# earlgrey register map
File version: 0.1
Address unit: 32 bits
Registers are 32-bit, read-write, no defined reset value unless marked. A register's access mark holds for its fields unless they carry their own. Offsets are from the block's base; [hi:lo] are bit positions.

## entropy_src — Filters and checks raw entropy bits from a random noise source and forwards them to CSRNG
Base 0x41160000
0x00 ME_REGWEN rw0c — Register write enable for module enable register
  [?] ? — When true, the !!MODULE_ENABLE register can be modified.When false, it becomes read-only.
0x20 SW_REGUPD rw0c — Register write enable for control and threshold registers
  [?] ? — When this bit true and the MODULE_ENABLE field is false,the REGWEN write enable bit read as true, and is distributed toall associated control and threshold registers.When false, these registers become read-only.
0x40 REGWEN ro — Register write enable for all control registers
  [?] ? — This read-only write enable bit will allow write accessto control and theshold registers that are associated with this bit,but only when the MODULE_ENABLE field is set to kMultiBitBool4False and theSW_REGUPD write enable bit is set to true.When read as false, these registers become read-only.
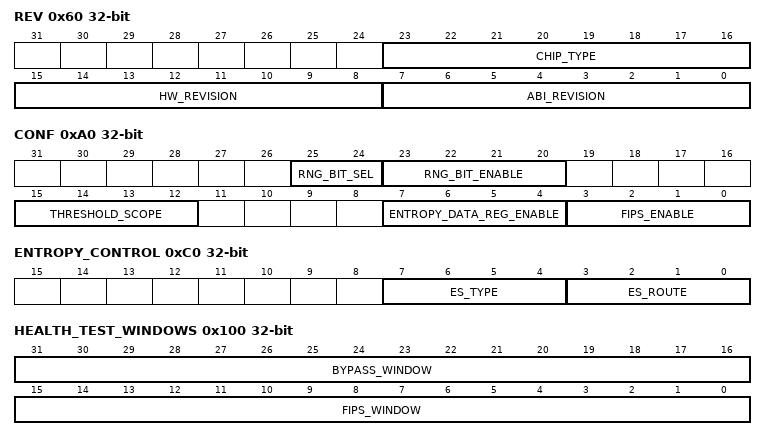
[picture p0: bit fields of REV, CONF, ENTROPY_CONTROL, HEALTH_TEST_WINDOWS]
0x60 REV ro — Revision register
  [23:16] CHIP_TYPE — Read of this register shows the type of chip using this block.
  [15:8] HW_REVISION — Read of this register shows the revision of this block.
  [7:0] ABI_REVISION — Read of this register shows the ABI of this block.
0x80 MODULE_ENABLE
  [3:0] MODULE_ENABLE — Setting this field to kMultiBitBool4True will enable the ENTROPY_SRC module. Settingthis field to kMultiBitBool4False will effectively reset the module. The modules ofthe entropy complex may only be enabled and disabled in a specific order, seeProgrammers Guide for details.
0xA0 CONF — Configuration register
  [25:24] RNG_BIT_SEL — When the above bit iset, this field selects which bit from the RNG bus willbe processed when in single RNG bit mode.This two bit field selects the RNG bit stream:0b00: RNG bit 00b01: RNG bit 10b10: RNG bit 20b11: RNG bit 3
  [23:20] RNG_BIT_ENABLE — Setting this field to kMultiBitBool4True enables the single RNG bit mode, where onlyone bit is sampled.
  [15:12] THRESHOLD_SCOPE — This field controls the scope (either by-line or by-sum) of the health checks.If set to kMultiBitBool4True, the Adaptive Proportion and Markov Tests will accumulate allRNG input lines into a single score, and thresholds will be applied to the sum allthe entropy input lines. If set to kMultiBitBool4False, the RNG input lines are all scoredindividually. A statistical deviation in any one input line, be it due tocoincidence or failure, will force rejection of the sample, and count toward thetotal alert count.
  [7:4] ENTROPY_DATA_REG_ENABLE — Setting this field to kMultiBitBool4True will enable reading entropy values from theENTROPY_DATA register. This function also requires that the otp_en_entropy_src_fw_readinput vector is set to the enable encoding.
  [3:0] FIPS_ENABLE — Setting this field to kMultiBitBool4True will enable FIPS qualified entropy to begenerated.
0xC0 ENTROPY_CONTROL
  [7:4] ES_TYPE — Setting this field to kMultiBitBool4True will bypass the conditioning logic and bring raw entropydata to the ENTROPY_DATA register. When kMultiBitBool4False, FIPS compliant entropywill be brought the ENTROPY_DATA register, after being conditioned.
  [3:0] ES_ROUTE — Setting this field to kMultiBitBool4True routes the generated entropy value to the ENTROPY_DATAregister to be read by firmware. When this field is kMultiBitBool4False, the generatedentropy will be forwarded out of this module to the hardware interface.
0xE0 ENTROPY_DATA ro — Entropy data bits
  [31:0] ? — A read of this register provides generated entropy bits to firmware.
0x100 HEALTH_TEST_WINDOWS
  [31:16] BYPASS_WINDOW — This is the window size for all health tests when running in bypass mode. This mode is active after reset for the first and only test run, or when this mode is programmed by firmware. The default value is (384 bits * 1 clock/4 bits); Note that currently only a window size of 384 is supported and tested (this corresponds to the register default value 0x60). Do not use any other values, unless you know what you are doing.
  [15:0] FIPS_WINDOW — This is the window size for all health tests. This value is used in normal mode when entropy is being tested in FIPS/CC compliance mode. The default value is (2048 bits * 1 clock/4 bits);
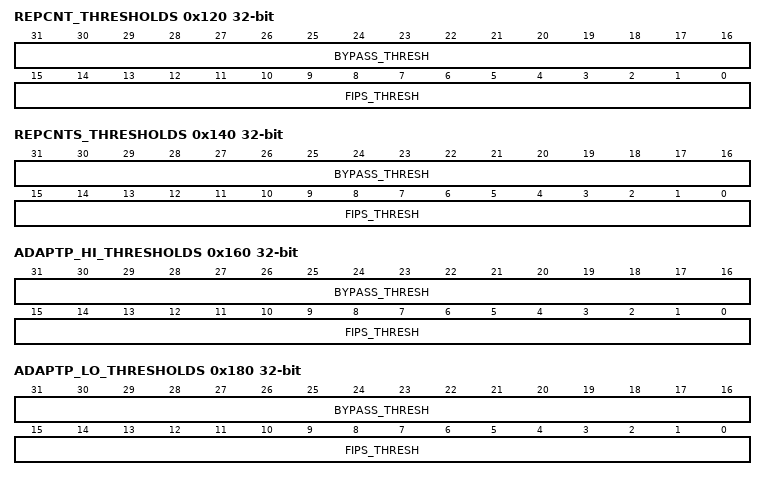
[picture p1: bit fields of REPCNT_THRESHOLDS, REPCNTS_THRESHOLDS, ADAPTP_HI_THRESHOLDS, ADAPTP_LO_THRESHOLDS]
0x120 REPCNT_THRESHOLDS — Repetition count test thresholds register
  [31:16] BYPASS_THRESH — This is the threshold size for the repetition count health test running in bypass mode. This mode is active after reset for the first and only test run, or when this mode is programmed by firmware. This register must be written before the module is enabled. Writing to this register will only update the register if the written value is less than the current value of this register. A read from this register always reflects the current value.
  [15:0] FIPS_THRESH — This is the threshold size for the repetition count health test. This value is used in normal mode when entropy is being tested in FIPS/CC compliance mode. This register must be written before the module is enabled. Writing to this register will only update the register if the written value is less than the current value of this register. A read from this register always reflects the current value.
0x140 REPCNTS_THRESHOLDS — Repetition count symbol test thresholds register
  [31:16] BYPASS_THRESH — This is the threshold size for the repetition count symbol health test running in bypass mode. This mode is active after reset for the first and only test run, or when this mode is programmed by firmware. This register must be written before the module is enabled. Writing to this register will only update the register if the written value is less than the current value of this register. A read from this register always reflects the current value.
  [15:0] FIPS_THRESH — This is the threshold size for the repetition count symbol health test. This value is used in normal mode when entropy is being tested in FIPS/CC compliance mode. This register must be written before the module is enabled. Writing to this register will only update the register if the written value is less than the current value of this register. A read from this register always reflects the current value.
0x160 ADAPTP_HI_THRESHOLDS — Adaptive proportion test high thresholds register
  [31:16] BYPASS_THRESH — This is the threshold size for the adaptive proportion health test running in bypass mode. This mode is active after reset for the first and only test run, or when this mode is programmed by firmware. This register must be written before the module is enabled. Writing to this register will only update the register if the written value is less than the current value of this register. A read from this register always reflects the current value.
  [15:0] FIPS_THRESH — This is the threshold size for the adaptive proportion health test. This value is used in normal mode when entropy is being tested in FIPS/CC compliance mode. This register must be written before the module is enabled. Writing to this register will only update the register if the written value is less than the current value of this register. A read from this register always reflects the current value.
0x180 ADAPTP_LO_THRESHOLDS — Adaptive proportion test low thresholds register
  [31:16] BYPASS_THRESH — This is the threshold size for the adaptive proportion health test running in bypass mode. This mode is active after reset for the first and only test run, or when this mode is programmed by firmware. This register must be written before the module is enabled. Writing to this register will only update the register if the written value is greater than the current value of this register. A read from this register always reflects the current value.
  [15:0] FIPS_THRESH — This is the threshold size for the adaptive proportion health test. This value is used in normal mode when entropy is being tested in FIPS/CC compliance mode. This register must be written before the module is enabled. Writing to this register will only update the register if the written value is greater than the current value of this register. A read from this register always reflects the current value.
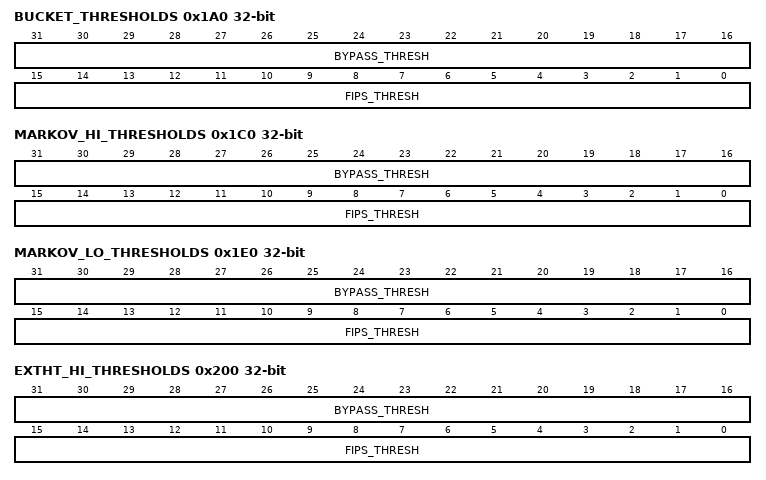
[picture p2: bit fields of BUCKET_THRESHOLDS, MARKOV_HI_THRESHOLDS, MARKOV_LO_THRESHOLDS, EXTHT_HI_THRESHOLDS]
0x1A0 BUCKET_THRESHOLDS — Bucket test thresholds register
  [31:16] BYPASS_THRESH — This is the threshold size for the bucket health test running in bypass mode. This mode is active after reset for the first and only test run, or when this mode is programmed by firmware. This register must be written before the module is enabled. Writing to this register will only update the register if the written value is less than the current value of this register. A read from this register always reflects the current value.
  [15:0] FIPS_THRESH — This is the threshold size for the bucket health test. This value is used in normal mode when entropy is being tested in FIPS/CC compliance mode. This register must be written before the module is enabled. Writing to this register will only update the register if the written value is less than the current value of this register. A read from this register always reflects the current value.
0x1C0 MARKOV_HI_THRESHOLDS — Markov test high thresholds register
  [31:16] BYPASS_THRESH — This is the threshold size for the Markov health test running in bypass mode. This mode is active after reset for the first and only test run, or when this mode is programmed by firmware. This register must be written before the module is enabled. Writing to this register will only update the register if the written value is less than the current value of this register. A read from this register always reflects the current value.
  [15:0] FIPS_THRESH — This is the threshold size for the Markov health test. This value is used in normal mode when entropy is being tested in FIPS/CC compliance mode. This register must be written before the module is enabled. Writing to this register will only update the register if the written value is less than the current value of this register. A read from this register always reflects the current value.
0x1E0 MARKOV_LO_THRESHOLDS — Markov test low thresholds register
  [31:16] BYPASS_THRESH — This is the threshold size for the Markov health test running in bypass mode. This mode is active after reset for the first and only test run, or when this mode is programmed by firmware. This register must be written before the module is enabled. Writing to this register will only update the register if the written value is greater than the current value of this register. A read from this register always reflects the current value.
  [15:0] FIPS_THRESH — This is the threshold size for the Markov health test. This value is used in normal mode when entropy is being tested in FIPS/CC compliance mode. This register must be written before the module is enabled. Writing to this register will only update the register if the written value is greater than the current value of this register. A read from this register always reflects the current value.
0x200 EXTHT_HI_THRESHOLDS — External health test high thresholds register
  [31:16] BYPASS_THRESH — This is the threshold size for the external health test running in bypass mode. This mode is active after reset for the first and only test run, or when this mode is programmed by firmware. This register must be written before the module is enabled. Writing to this register will only update the register if the written value is less than the current value of this register. A read from this register always reflects the current value.
  [15:0] FIPS_THRESH — This is the threshold size for the external health test. This value is used in normal mode when entropy is being tested in FIPS/CC compliance mode. This register must be written before the module is enabled. Writing to this register will only update the register if the written value is less than the current value of this register. A read from this register always reflects the current value.
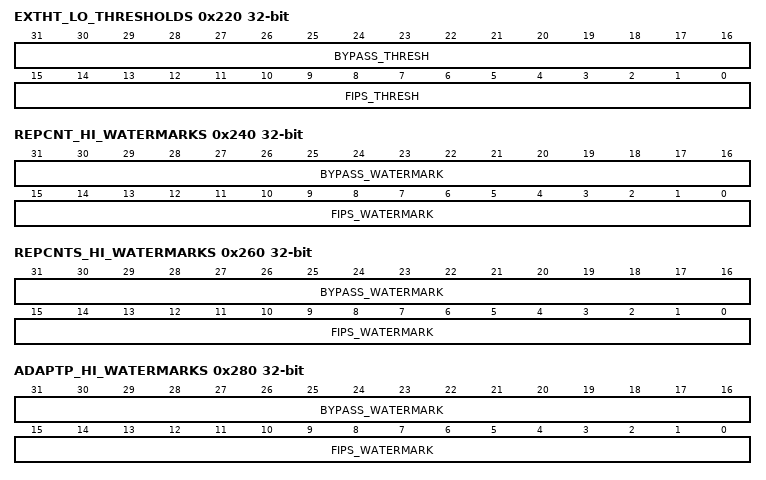
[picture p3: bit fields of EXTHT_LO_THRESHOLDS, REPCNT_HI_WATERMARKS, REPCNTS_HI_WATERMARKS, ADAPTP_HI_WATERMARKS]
0x220 EXTHT_LO_THRESHOLDS — External health test low thresholds register
  [31:16] BYPASS_THRESH — This is the threshold size for the external health test running in bypass mode. This mode is active after reset for the first and only test run, or when this mode is programmed by firmware. This register must be written before the module is enabled. Writing to this register will only update the register if the written value is greater than the current value of this register. A read from this register always reflects the current value.
  [15:0] FIPS_THRESH — This is the threshold size for the external health test. This value is used in normal mode when entropy is being tested in FIPS/CC compliance mode. This register must be written before the module is enabled. Writing to this register will only update the register if the written value is greater than the current value of this register. A read from this register always reflects the current value.
0x240 REPCNT_HI_WATERMARKS ro — Repetition count test high watermarks register
  [31:16] BYPASS_WATERMARK — High watermark value of the REPCNT test in bypass mode.
  [15:0] FIPS_WATERMARK — High watermark value of the REPCNT test in FIPS mode.
0x260 REPCNTS_HI_WATERMARKS ro — Repetition count symbol test high watermarks register
  [31:16] BYPASS_WATERMARK — High watermark value of the REPCNTS test in bypass mode.
  [15:0] FIPS_WATERMARK — High watermark value of the REPCNTS test in FIPS mode.
0x280 ADAPTP_HI_WATERMARKS ro — Adaptive proportion test high watermarks register
  [31:16] BYPASS_WATERMARK — High watermark value of the adaptive proportion test in bypass mode.
  [15:0] FIPS_WATERMARK — High watermark value of the adaptive proportion test in FIPS mode.
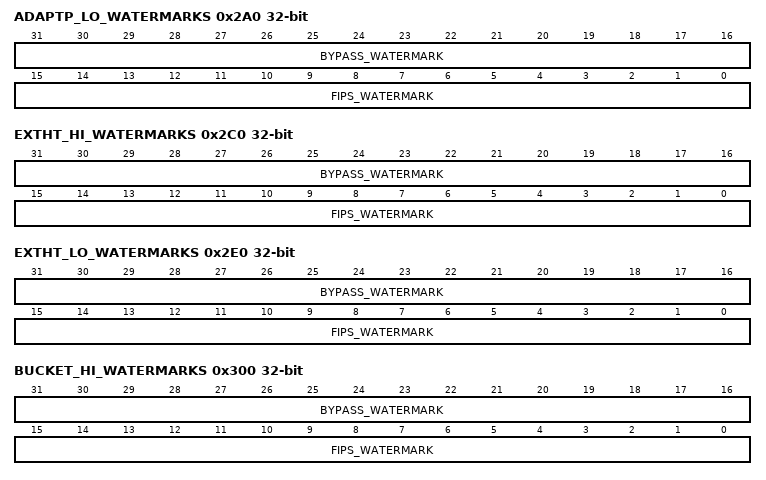
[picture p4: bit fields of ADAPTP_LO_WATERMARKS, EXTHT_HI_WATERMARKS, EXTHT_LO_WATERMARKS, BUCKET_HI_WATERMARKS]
0x2A0 ADAPTP_LO_WATERMARKS ro — Adaptive proportion test low watermarks register
  [31:16] BYPASS_WATERMARK — Low watermark value of the adaptive proportion test in bypass mode.
  [15:0] FIPS_WATERMARK — Low watermark value of the adaptive proportion test in FIPS mode.
0x2C0 EXTHT_HI_WATERMARKS ro — External health test high watermarks register
  [31:16] BYPASS_WATERMARK — High watermark value of the external health test in bypass mode.
  [15:0] FIPS_WATERMARK — High watermark value of the external health test in FIPS mode.
0x2E0 EXTHT_LO_WATERMARKS ro — External health test low watermarks register
  [31:16] BYPASS_WATERMARK — Low watermark value of the external health test in bypass mode.
  [15:0] FIPS_WATERMARK — Low watermark value of the external health test in FIPS mode.
0x300 BUCKET_HI_WATERMARKS ro — Bucket test high watermarks register
  [31:16] BYPASS_WATERMARK — High watermark value of the bucket test in bypass mode.
  [15:0] FIPS_WATERMARK — High watermark value of the bucket test in FIPS mode.
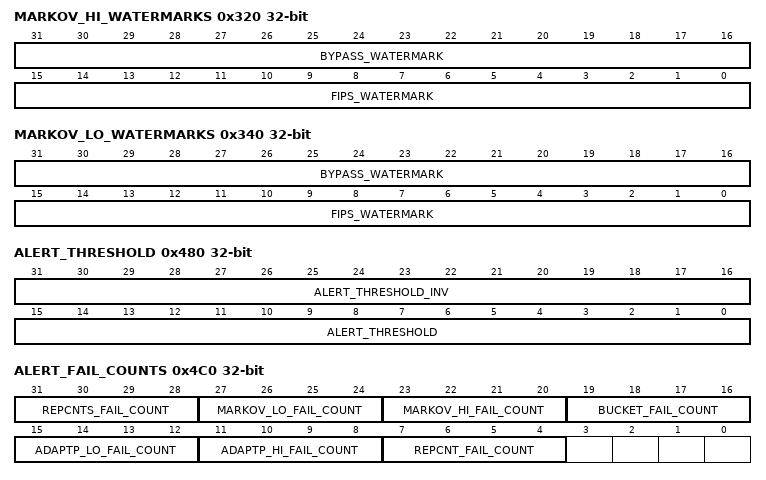
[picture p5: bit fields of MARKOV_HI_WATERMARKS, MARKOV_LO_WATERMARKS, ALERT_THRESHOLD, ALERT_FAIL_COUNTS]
0x320 MARKOV_HI_WATERMARKS ro — Markov test high watermarks register
  [31:16] BYPASS_WATERMARK — High watermark value of the Markov test in bypass mode.
  [15:0] FIPS_WATERMARK — High watermark value of the Markov test in FIPS mode.
0x340 MARKOV_LO_WATERMARKS ro — Markov test low watermarks register
  [31:16] BYPASS_WATERMARK — Low watermark value of the Markov test in bypass mode.
  [15:0] FIPS_WATERMARK — Low watermark value of the Markov test in FIPS mode.
0x360 REPCNT_TOTAL_FAILS ro — Repetition count test failure counter register
  [31:0] REPCNT_TOTAL_FAILS — This register will hold a running count of test failures observed during normal operation. It will persist until cleared.
0x380 REPCNTS_TOTAL_FAILS ro — Repetition count symbol test failure counter register
  [31:0] REPCNTS_TOTAL_FAILS — This register will hold a running count of test failures observed during normal operation. It will persist until cleared.
0x3A0 ADAPTP_HI_TOTAL_FAILS ro — Adaptive proportion high test failure counter register
  [31:0] ADAPTP_HI_TOTAL_FAILS — This register will hold a running count of test failures observed during normal operation. It will persist until cleared.
0x3C0 ADAPTP_LO_TOTAL_FAILS ro — Adaptive proportion low test failure counter register
  [31:0] ADAPTP_LO_TOTAL_FAILS — This register will hold a running count of test failures observed during normal operation. It will persist until cleared.
0x3E0 BUCKET_TOTAL_FAILS ro — Bucket test failure counter register
  [31:0] BUCKET_TOTAL_FAILS — This register will hold a running count of test failures observed during normal operation. It will persist until cleared.
0x400 MARKOV_HI_TOTAL_FAILS ro — Markov high test failure counter register
  [31:0] MARKOV_HI_TOTAL_FAILS — This register will hold a running count of test failures observed during normal operation. It will persist until cleared.
0x420 MARKOV_LO_TOTAL_FAILS ro — Markov low test failure counter register
  [31:0] MARKOV_LO_TOTAL_FAILS — This register will hold a running count of test failures observed during normal operation. It will persist until cleared.
0x440 EXTHT_HI_TOTAL_FAILS ro — External health test high threshold failure counter register
  [31:0] EXTHT_HI_TOTAL_FAILS — This register will hold a running count of test failures observed during normal operation. It will persist until cleared.
0x460 EXTHT_LO_TOTAL_FAILS ro — External health test low threshold failure counter register
  [31:0] EXTHT_LO_TOTAL_FAILS — This register will hold a running count of test failures observed during normal operation. It will persist until cleared.
0x480 ALERT_THRESHOLD
  [31:16] ALERT_THRESHOLD_INV — This should be set to the value above, but inverted.
  [15:0] ALERT_THRESHOLD — This is the threshold size that will signal an alert when value is reached. A value of zero will disable alerts. The default value is 2.
0x4A0 ALERT_SUMMARY_FAIL_COUNTS ro — Alert summary failure counts register
  [15:0] ANY_FAIL_COUNT — This field will hold a running count of the total alert count, which is a sum of all of the other counters in the !!ALERT_FAIL_COUNTS register. It will be reset after every passing test sequence. If an alert is signaled, this value will persist until it is cleared.
0x4C0 ALERT_FAIL_COUNTS ro — Alert failure counts register
  [31:28] REPCNTS_FAIL_COUNT — This field will hold a running count of test failures that contribute to the total alert count. It will be reset after every passing test sequence. If an alert is signaled, this value will persist until it is cleared.
  [27:24] MARKOV_LO_FAIL_COUNT — This field will hold a running count of test failures that contribute to the total alert count. It will be reset after every passing test sequence. If an alert is signaled, this value will persist until it is cleared.
  [23:20] MARKOV_HI_FAIL_COUNT — This field will hold a running count of test failures that contribute to the total alert count. It will be reset after every passing test sequence. If an alert is signaled, this value will persist until it is cleared.
  [19:16] BUCKET_FAIL_COUNT — This field will hold a running count of test failures that contribute to the total alert count. It will be reset after every passing test sequence. If an alert is signaled, this value will persist until it is cleared.
  [15:12] ADAPTP_LO_FAIL_COUNT — This field will hold a running count of test failures that contribute to the total alert count. It will be reset after every passing test sequence. If an alert is signaled, this value will persist until it is cleared.
  [11:8] ADAPTP_HI_FAIL_COUNT — This field will hold a running count of test failures that contribute to the total alert count. It will be reset after every passing test sequence. If an alert is signaled, this value will persist until it is cleared.
  [7:4] REPCNT_FAIL_COUNT — This field will hold a running count of test failures that contribute to the total alert count. It will be reset after every passing test sequence. If an alert is signaled, this value will persist until it is cleared.
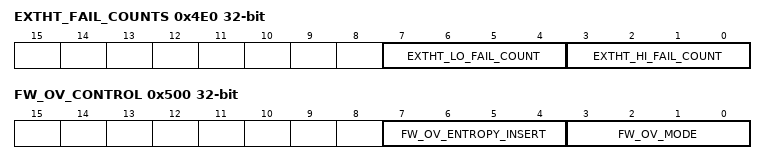
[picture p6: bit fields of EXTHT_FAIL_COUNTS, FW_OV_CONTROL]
0x4E0 EXTHT_FAIL_COUNTS ro — External health test alert failure counts register
  [7:4] EXTHT_LO_FAIL_COUNT — This field will hold a running count of test failures that contribute to the total alert count. It will be reset after every passing test sequence. If an alert is signaled, this value will persist until it is cleared.
  [3:0] EXTHT_HI_FAIL_COUNT — This field will hold a running count of test failures that contribute to the total alert count. It will be reset after every passing test sequence. If an alert is signaled, this value will persist until it is cleared.
0x500 FW_OV_CONTROL — Firmware override control register
  [7:4] FW_OV_ENTROPY_INSERT — Setting this field to kMultiBitBool4True will switch the input into the pre-conditionerpacker FIFO. Firmware can directly write into the packer FIFO, enablingthe ability to insert entropy bits back into the hardware flow. Firmwarecan read data from the health check packer FIFO, then do optional healthchecks or optional conditioning, then insert the results back into the flow.Also, the !!FW_OV_CONTROL.FW_OV_MODE bit must be set.
  [3:0] FW_OV_MODE — Setting this field to kMultiBitBool4True will put the entropy flow in firmware override mode.In this mode, firmware can monitor the post-health test entropy by readingthe observe FIFO. This function also requires that the otp_en_entropy_src_fw_overinput vector is set to the enable encoding.
0x520 FW_OV_SHA3_START — Firmware override sha3 block start control register
  [3:0] FW_OV_INSERT_START — Setting this field to kMultiBitBool4True will instruct the ENTROPY_SRC main state machineto start the SHA3 process and be ready to accept entropy data. This field shouldbe set prior to writting the FW_OV_WR_DATA register. Once all data has been written,this field should be set to kMultiBitBool4False. Once that happened, the SHA3 block will finishprocessing and push the result into the ESFINAL FIFO.Note that clearing this bit to kMultiBitBool4False while there is still unprocessedentropy in the !!FW_OV_WR_DATA will start the SHA3 engine before data can be addedto the input message, and will also signal a recoverable alert in!!RECOV_ALERT_STS.ES_FW_OV_DISABLE_ALERT. To avoid this, check that!!FW_OV_WR_FIFO_FULL is clear before setting this field to kMultiBitBool4False.
0x540 FW_OV_WR_FIFO_FULL ro — Firmware override FIFO write full status register
  [?] FW_OV_WR_FIFO_FULL — "When this bit is clear, writes to the FW_OV_WR_DATA register are allowed.If this bit is set, it is the equivalent to a FIFO full condition, and writesto the FW_OV_WR_DATA register must be delayed until this bit is reset.
0x560 FW_OV_RD_FIFO_OVERFLOW rw0c — Firmware override Observe FIFO overflow status
  [?] FW_OV_RD_FIFO_OVERFLOW — This bit is set by hardware whenever RNG data is lost due to an overflow conditionin the Observe FIFO. The RNG data rate is slow enough that firmware should alwaysbe able to keep up. This register meanwhile provides an additional check to confirmthat bytes read from the !!FW_OV_RD_DATA register represent contiguous RNG samples.If an overflow event occurs, this bit must be cleared by software.
0x580 FW_OV_RD_DATA ro — Firmware override Observe FIFO read register
  [31:0] ? — A read of this register pops and returns the top of the Observe FIFO.
0x5A0 FW_OV_WR_DATA wo — Firmware override FIFO write register
  [31:0] ? — A write to this register will insert entropy back into the entropy sourcemodule flow. Both !!FW_OV_CONTROL.FW_OV_MODE and !!FW_OV_CONTROL.FW_OV_ENTROPY_INSERT bits need to be setto enable the insertion.
0x5C0 OBSERVE_FIFO_THRESH — Observe FIFO threshold register
  [6:0] ? — This field will set the threshold that the depth of the Observe FIFOwill be compared with when setting the interrupt status bit.Note: a value of zero is reserved and not to be used.
0x5E0 OBSERVE_FIFO_DEPTH ro
  [6:0] ? — This field will hold the current depth of the Observe FIFO.
0x600 DEBUG_STATUS ro
  [5:3] SHA3_FSM — This is the SHA3 finite state machine current state.
  [2:0] ENTROPY_FIFO_DEPTH — This is the depth of the entropy source FIFO.
  [?] SHA3_BLOCK_PR — This is the SHA3 block processed signal current state.
  [?] SHA3_SQUEEZING — This is the SHA3 squeezing signal current state.
  [?] SHA3_ABSORBED — This is the SHA3 absorbed signal current state.
  [?] SHA3_ERR — This is a logic-or of all of the SHA3 error signals.
  [?] MAIN_SM_IDLE — The entropy_src main state machine is in the idle state.
  [?] MAIN_SM_BOOT_DONE — The entropy_src main state machine is in the boot phase done state.
0x620 RECOV_ALERT_STS rw0c — Recoverable alert status register
  [?] FIPS_ENABLE_FIELD_ALERT — This bit is set when the FIPS_ENABLE field in the !!CONF register is set toa value other than kMultiBitBool4False or kMultiBitBool4True.Writing a zero resets this status bit.
  [?] ENTROPY_DATA_REG_EN_FIELD_ALERT — This bit is set when the ENTROPY_DATA_REG_ENABLE field in the !!CONF register is set toa value other than kMultiBitBool4False or kMultiBitBool4True.Writing a zero resets this status bit.
  [?] MODULE_ENABLE_FIELD_ALERT — This bit is set when the MODULE_ENABLE field in the !!MODULE_ENABLE register is set toa value other than kMultiBitBool4False or kMultiBitBool4True.Writing a zero resets this status bit.
  [?] THRESHOLD_SCOPE_FIELD_ALERT — This bit is set when the THRESHOLD_SCOPE field in the !!CONF register is set toa value other than kMultiBitBool4False or kMultiBitBool4True.Writing a zero resets this status bit.
  [?] RNG_BIT_ENABLE_FIELD_ALERT — This bit is set when the RNG_BIT_ENABLE field in the !!CONF register is set toa value other than kMultiBitBool4False or kMultiBitBool4True.Writing a zero resets this status bit.
  [?] FW_OV_SHA3_START_FIELD_ALERT — This bit is set when the FW_OV_SHA3_START field in the !!FW_OV_SHA3_START register is set toa value other than kMultiBitBool4False or kMultiBitBool4True.Writing a zero resets this status bit.
  [?] FW_OV_MODE_FIELD_ALERT — This bit is set when the FW_OV_MODE field in the !!FW_OV_CONTROL register is set toa value other than kMultiBitBool4False or kMultiBitBool4True.Writing a zero resets this status bit.
  [?] FW_OV_ENTROPY_INSERT_FIELD_ALERT — This bit is set when the FW_OV_ENTROPY_INSERT field in the !!FW_OV_CONTROL register is set toa value other than kMultiBitBool4False or kMultiBitBool4True.Writing a zero resets this status bit.
  [?] ES_ROUTE_FIELD_ALERT — This bit is set when the ES_ROUTE field in the !!ENTROPY_CONTROL register is set toa value other than kMultiBitBool4False or kMultiBitBool4True.Writing a zero resets this status bit.
  [?] ES_TYPE_FIELD_ALERT — This bit is set when the ES_TYPE field in the !!ENTROPY_CONTROL register is set toa value other than kMultiBitBool4False or kMultiBitBool4True.Writing a zero resets this status bit.
  [?] ES_MAIN_SM_ALERT — This bit is set when the main state machine detects a threshhold failure state.Writing a zero resets this status bit.
  [?] ES_BUS_CMP_ALERT — This bit is set when the interal entropy bus value is equal to the priorvalid value on the bus, indicating a possible attack.Writing a zero resets this status bit.
  [?] ES_THRESH_CFG_ALERT — This bit is set when the !!ALERT_THRESHOLD register is not configured properly.The upper field must be the exact inverse of the lower field.Writing a zero resets this status bit.
  [?] ES_FW_OV_WR_ALERT — This bit is set when the packer FIFO has been written but was full at the time,and in both FW_OV_MODE and FW_OV_ENTROPY_INSERT modes.This alert would normally be the result of not monitoring the !!FW_OV_WR_FIFO_FULLregister before each write to the !!FW_OV_WR_DATA register.Writing a zero resets this status bit.
  [?] ES_FW_OV_DISABLE_ALERT — This bit is set when !!FW_OV_SHA3_START has been set to MuBi4 False, withoutwaiting for the FW_OV packer FIFO to clear. The final entropy entry in the FIFOwill not be included in the SHA3 digest. (Rather it will be added to thesubsequent SHA3 digest.) To avoid this alert, monitor !!FW_OV_WR_FIFO_FULL beforeclearing !!FW_OV_SHA3_START. This alert only applies when both FW_OV_MODE andFW_OV_ENTROPY_INSERT are set to MuBi4True.Writing a zero resets this status bit.
0x640 ERR_CODE ro — Hardware detection of error conditions status register
  [?] SFIFO_ESRNG_ERR — This bit will be set to one when an error has been detected for theesrng FIFO. The type of error is reflected in the type statusbits (bits 28 through 30 of this register).This bit will stay set until the next reset.
  [?] SFIFO_OBSERVE_ERR — This bit will be set to one when an error has been detected for theobserve FIFO. The type of error is reflected in the type statusbits (bits 28 through 30 of this register).This bit will stay set until the next reset.
  [?] SFIFO_ESFINAL_ERR — This bit will be set to one when an error has been detected for theesfinal FIFO. The type of error is reflected in the type statusbits (bits 28 through 30 of this register).This bit will stay set until the next reset.
  [?] ES_ACK_SM_ERR — This bit will be set to one when an illegal state has been detected for theES ack stage state machine. This error will signal a fatal alert, and alsoan interrupt if enabled.This bit will stay set until the next reset.
  [?] ES_MAIN_SM_ERR — This bit will be set to one when an illegal state has been detected for theES main stage state machine. This error will signal a fatal alert, and alsoan interrupt if enabled.This bit will stay set until the next reset.
  [?] ES_CNTR_ERR — This bit will be set to one when a hardened counter has detected an errorcondition. This error will signal a fatal alert, and alsoan interrupt if enabled.This bit will stay set until the next reset.
  [?] SHA3_STATE_ERR — This bit will be set to one when a SHA3 state error has been detected.This error will signal a fatal alert, and also an interrupt if enabled.This bit will stay set until the next reset.
  [?] SHA3_RST_STORAGE_ERR — This bit will be set to one when a SHA3_RST_STORAGE_ERR signal beingactive has been detected.This error will signal a fatal alert, and also an interrupt if enabled.This bit will stay set until the next reset.
  [?] FIFO_WRITE_ERR — This bit will be set to one when any of the source bits (bits 0 through 1 of thisthis register) are asserted as a result of an error pulse generated fromany full FIFO that has been recieved a write pulse.This bit will stay set until the next reset.
  [?] FIFO_READ_ERR — This bit will be set to one when any of the source bits (bits 0 through 1 of thisthis register) are asserted as a result of an error pulse generated fromany empty FIFO that has recieved a read pulse.This bit will stay set until the next reset.
  [?] FIFO_STATE_ERR — This bit will be set to one when any of the source bits (bits 0 through 1 of thisthis register) are asserted as a result of an error pulse generated fromany FIFO where both the empty and full status bits are set.This bit will stay set until the next reset.
0x660 ERR_CODE_TEST — Test error conditions register
  [4:0] ERR_CODE_TEST — Setting this field will set the bit number for which an errorwill be forced in the hardware. This bit number is that same onefound in the !!ERR_CODE register. The action of writing thisregister will force an error pulse. The sole purpose of thisregister is to test that any error properly propagates to eitheran interrupt or an alert.
0x680 MAIN_SM_STATE ro — Main state machine state debug register
  [8:0] MAIN_SM_STATE — This is the state of the ENTROPY_SRC main state machine.See the RTL file `entropy_src_main_sm` for the meaning of the values.
